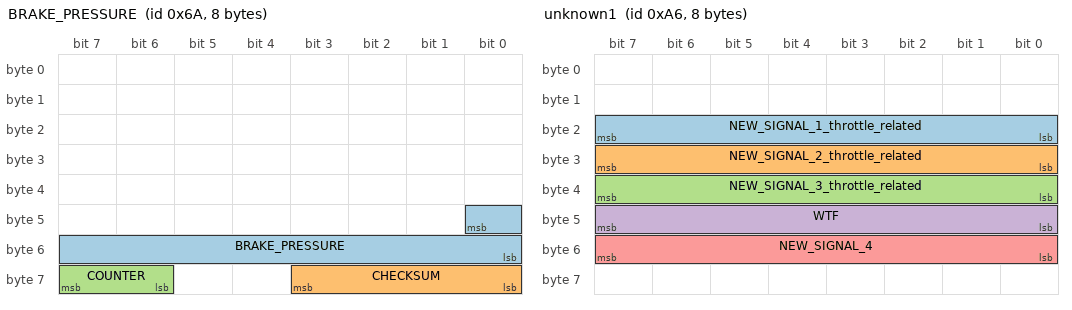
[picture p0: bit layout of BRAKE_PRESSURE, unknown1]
BO_ 106 BRAKE_PRESSURE: 8 VSA
 SG_ BRAKE_PRESSURE : 40|9@0+ (1,-103) [0|1] "" XXX
 SG_ CHECKSUM : 59|4@0+ (1,0) [0|15] "" XXX
 SG_ COUNTER : 63|2@0+ (1,0) [0|3] "" XXX

BO_ 166 unknown1: 8 XXX
 SG_ NEW_SIGNAL_1_throttle_related : 23|8@0+ (1,0) [0|255] "" XXX
 SG_ NEW_SIGNAL_2_throttle_related : 31|8@0+ (1,0) [0|255] "" XXX
 SG_ NEW_SIGNAL_3_throttle_related : 39|8@0+ (1,0) [0|255] "" XXX
 SG_ WTF : 47|8@0+ (1,0) [0|255] "" XXX
 SG_ NEW_SIGNAL_4 : 55|8@0+ (1,0) [0|255] "" XXX

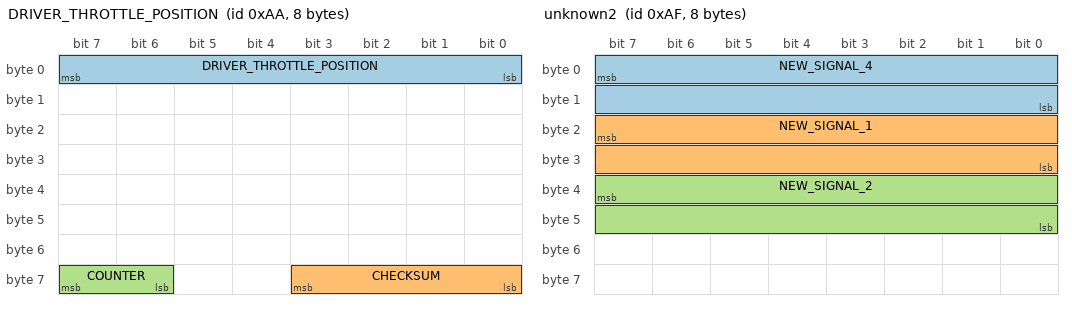
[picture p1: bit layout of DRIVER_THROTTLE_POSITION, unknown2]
BO_ 170 DRIVER_THROTTLE_POSITION: 8 PCM
 SG_ DRIVER_THROTTLE_POSITION : 7|8@0+ (1,0) [0|255] "" XXX
 SG_ CHECKSUM : 59|4@0+ (1,0) [0|15] "" XXX
 SG_ COUNTER : 63|2@0+ (1,0) [0|3] "" XXX

BO_ 175 unknown2: 8 XXX
 SG_ NEW_SIGNAL_4 : 7|16@0+ (1,0) [0|65535] "" XXX
 SG_ NEW_SIGNAL_1 : 23|16@0+ (1,0) [0|65535] "" XXX
 SG_ NEW_SIGNAL_2 : 39|16@0+ (1,0) [0|65535] "" XXX

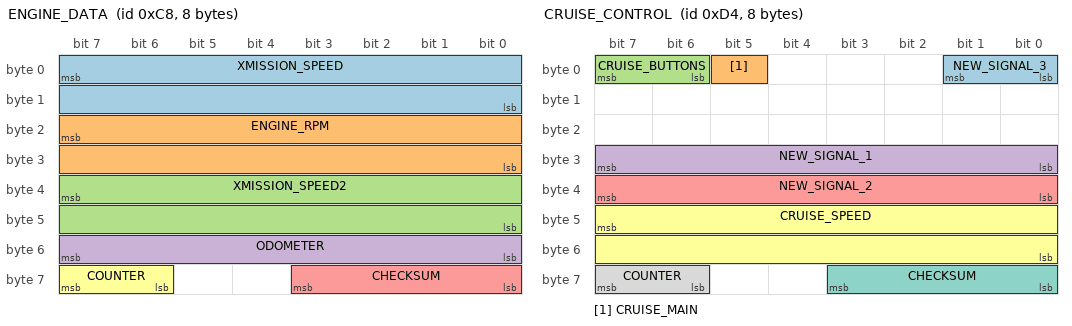
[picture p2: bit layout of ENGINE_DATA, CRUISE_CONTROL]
BO_ 200 ENGINE_DATA: 8 PCM
 SG_ XMISSION_SPEED : 7|16@0+ (0.01,0) [0|250] "kph" XXX
 SG_ ENGINE_RPM : 23|16@0+ (1,0) [0|15000] "rpm" XXX
 SG_ XMISSION_SPEED2 : 39|16@0+ (0.01,0) [0|250] "kph" XXX
 SG_ ODOMETER : 55|8@0+ (10,0) [0|2550] "m" XXX
 SG_ CHECKSUM : 59|4@0+ (1,0) [0|15] "" XXX
 SG_ COUNTER : 63|2@0+ (1,0) [0|3] "" XXX

BO_ 212 CRUISE_CONTROL: 8 PCM
 SG_ NEW_SIGNAL_3 : 1|2@0+ (1,0) [0|3] "" XXX
 SG_ CRUISE_MAIN : 5|1@0+ (1,0) [0|1] "" XXX
 SG_ CRUISE_BUTTONS : 7|2@0+ (1,0) [0|3] "" XXX
 SG_ NEW_SIGNAL_1 : 31|8@0+ (1,0) [0|127] "" XXX
 SG_ NEW_SIGNAL_2 : 39|8@0+ (1,0) [0|255] "" XXX
 SG_ CRUISE_SPEED : 47|16@0+ (0.01,0) [0|65535] "kph" XXX
 SG_ CHECKSUM : 59|4@0+ (1,0) [0|15] "" XXX
 SG_ COUNTER : 63|2@0+ (1,0) [0|3] "" XXX

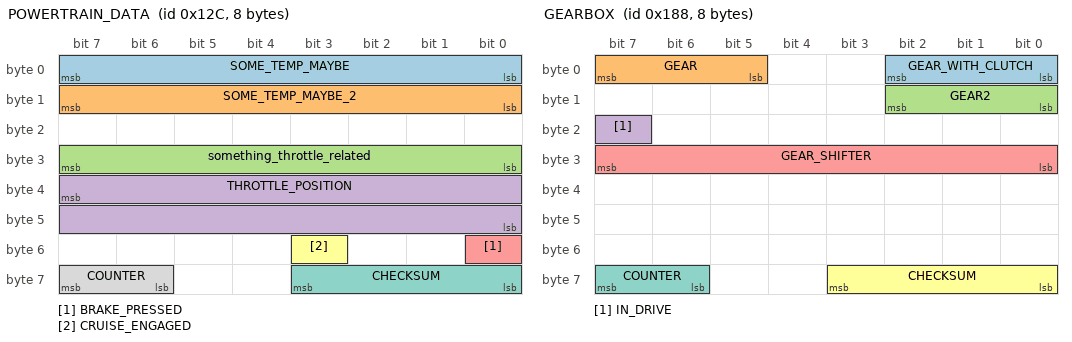
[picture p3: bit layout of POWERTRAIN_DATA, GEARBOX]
BO_ 300 POWERTRAIN_DATA: 8 PCM
 SG_ SOME_TEMP_MAYBE : 7|8@0+ (1,0) [0|255] "" XXX
 SG_ SOME_TEMP_MAYBE_2 : 15|8@0+ (1,0) [0|31] "" XXX
 SG_ something_throttle_related : 31|8@0+ (1,0) [0|255] "" XXX
 SG_ THROTTLE_POSITION : 39|16@0+ (1,0) [0|65535] "" XXX
 SG_ BRAKE_PRESSED : 48|1@0+ (1,0) [0|1] "" XXX
 SG_ CRUISE_ENGAGED : 51|1@0+ (1,0) [0|1] "" XXX
 SG_ CHECKSUM : 59|4@0+ (1,0) [0|15] "" XXX
 SG_ COUNTER : 63|2@0+ (1,0) [0|3] "" XXX

BO_ 392 GEARBOX: 8 PCM
 SG_ GEAR_WITH_CLUTCH : 2|3@0+ (1,0) [0|7] "" XXX
 SG_ GEAR : 7|3@0+ (1,0) [0|7] "" XXX
 SG_ GEAR2 : 10|3@0+ (1,0) [0|7] "" XXX
 SG_ IN_DRIVE : 23|1@0+ (1,0) [0|1] "" XXX
 SG_ GEAR_SHIFTER : 24|8@1+ (1,0) [0|65535] "" XXX
 SG_ CHECKSUM : 59|4@0+ (1,0) [0|15] "" XXX
 SG_ COUNTER : 63|2@0+ (1,0) [0|3] "" XXX

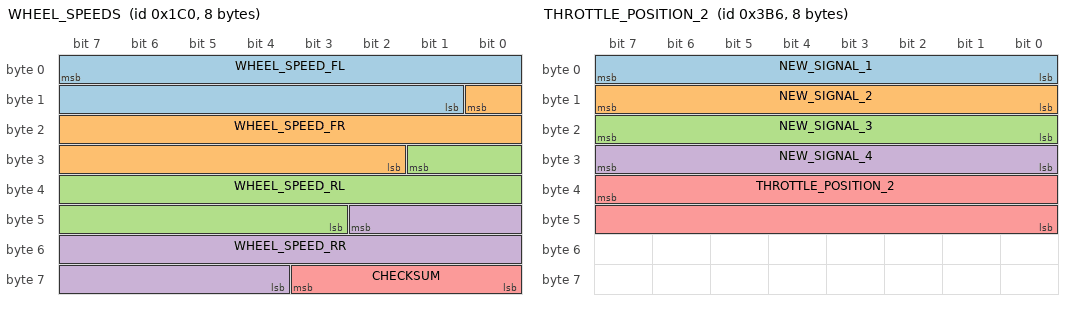
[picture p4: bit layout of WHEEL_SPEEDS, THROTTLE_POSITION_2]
BO_ 448 WHEEL_SPEEDS: 8 VSA
 SG_ WHEEL_SPEED_FL : 7|15@0+ (0.01,0) [0|250] "kph" XXX
 SG_ WHEEL_SPEED_FR : 8|15@0+ (0.01,0) [0|250] "kph" XXX
 SG_ WHEEL_SPEED_RL : 25|15@0+ (0.01,0) [0|250] "kph" XXX
 SG_ WHEEL_SPEED_RR : 42|15@0+ (0.01,0) [0|250] "kph" XXX
 SG_ CHECKSUM : 59|4@0+ (1,0) [0|15] "" XXX

BO_ 500 LIGHTS: 8 BDY
 SG_ LEFT_TURN_SIGNAL : 5|1@0+ (1,0) [0|1] "" XXX
 SG_ RIGHT_TURN_SIGNAL : 6|1@0+ (1,0) [0|1] "" XXX
 SG_ HEADLIGHTS_ON : 11|1@0+ (1,0) [0|1] "" XXX
 SG_ HEADLIGHTS : 13|4@0+ (1,0) [0|15] "" XXX
 SG_ NEW_SIGNAL_1 : 44|5@0+ (1,0) [0|31] "" XXX

BO_ 524 THROTTLE_POSITION_3: 8 XXX
 SG_ THROTTLE_POSITION_3 : 39|16@0+ (1,0) [0|65535] "" XXX

BO_ 548 useless_counter: 8 XXX
 SG_ NEW_SIGNAL_2 : 9|2@0+ (1,0) [0|3] "" XXX
 SG_ NEW_SIGNAL_1 : 23|16@0+ (1,0) [0|65535] "" XXX

BO_ 740 UNKNOWN_TEMP_SENSOR: 8 XXX
 SG_ SOME_TEMP_SENSOR : 7|8@0+ (1,0) [0|255] "" XXX

BO_ 947 unknown3: 8 XXX
 SG_ NEW_SIGNAL_1 : 23|8@0+ (1,0) [0|255] "" XXX

BO_ 949 unknown4: 8 XXX
 SG_ NEW_SIGNAL_1_possibly_throttle_pressed : 31|8@0+ (1,0) [0|255] "" XXX

BO_ 950 THROTTLE_POSITION_2: 8 XXX
 SG_ NEW_SIGNAL_1 : 7|8@0+ (1,0) [0|255] "" XXX
 SG_ NEW_SIGNAL_2 : 15|8@0+ (1,0) [0|255] "" XXX
 SG_ NEW_SIGNAL_3 : 23|8@0+ (1,0) [0|255] "" XXX
 SG_ NEW_SIGNAL_4 : 31|8@0+ (1,0) [0|255] "" XXX
 SG_ THROTTLE_POSITION_2 : 39|16@0+ (1,0) [0|65535] "" XXX

BO_ 953 unknown5: 8 XXX
 SG_ NEW_SIGNAL_1_possibly_brake_pressure_correlated : 47|8@0+ (1,0) [0|255] "" XXX
 SG_ NEW_SIGNAL_2_possibly_brake_pressure_correlated : 55|8@0+ (1,0) [0|255] "" XXX

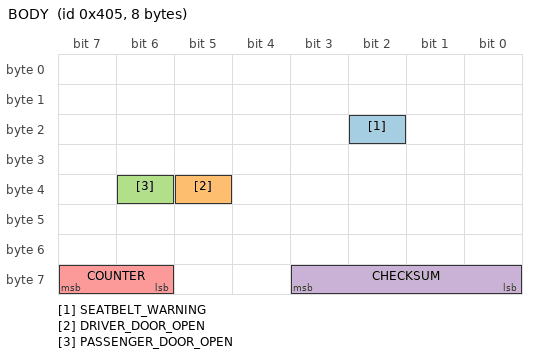
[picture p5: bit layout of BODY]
BO_ 1029 BODY: 8 BDY
 SG_ SEATBELT_WARNING : 18|1@0+ (1,0) [0|1] "" XXX
 SG_ DRIVER_DOOR_OPEN : 37|1@0+ (1,0) [0|1] "" XXX
 SG_ PASSENGER_DOOR_OPEN : 38|1@0+ (1,0) [0|1] "" XXX
 SG_ CHECKSUM : 59|4@0+ (1,0) [0|15] "" XXX
 SG_ COUNTER : 63|2@0+ (1,0) [0|3] "" XXX

CM_ SG_ 392 GEAR_WITH_CLUTCH "7 = clutch";
VAL_ 392 GEAR_SHIFTER 1 "P" 2 "R" 4 "N" 8 "D" 64 "L" 128 "L";
